# PY32F071Cxx register map
Vendor: Puya; Series: PY32F0; File version: 1.0.0
CPU: CM0+ r0p1, little endian, no MPU, no FPU, 4 interrupt priority bits
Registers are 32-bit, read-write, reset 0x0 unless marked. A register's access mark holds for its fields unless they carry their own. Offsets are from the block's base; [hi:lo] are bit positions; {n}, {i} and the like mark numbered series.

## OPA — des OPA
Base 0x40010300
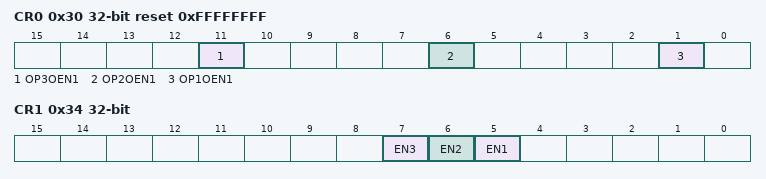
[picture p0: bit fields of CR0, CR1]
0x30 CR0 reset 0xFFFFFFFF
  [11] OP3OEN1, [6] OP2OEN1, [1] OP1OEN1
0x34 CR1
  [7] EN3, [6] EN2, [5] EN1

## PWR — Power control
Base 0x40007000
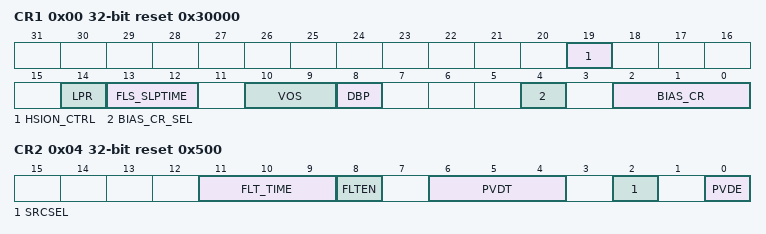
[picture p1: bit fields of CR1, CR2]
0x00 CR1 reset 0x30000 — Power control register 1
  [19] HSION_CTRL — HSI open time control
  [14] LPR — Low-power run
  [13:12] FLS_SLPTIME — Flash wait time after wakeup from the stop mode
  [10:9] VOS — Voltage scaling range selection
  [8] DBP — Disable backup domain write protection
  [4] BIAS_CR_SEL — MR Bias current selection
  [2:0] BIAS_CR — MR Bias current
0x04 CR2 reset 0x500 — Power control register 2
  [11:9] FLT_TIME — Digital filter time configuration
  [8] FLTEN — Digital filter enable
  [6:4] PVDT — Power voltage detector threshold selection
  [2] SRCSEL — Power voltage detector volatage selection
  [0] PVDE — Power voltage detector enable
0x14 SR ro — Power status register
  [11] PVDO — PVD output

## RTC
Base 0x40002800
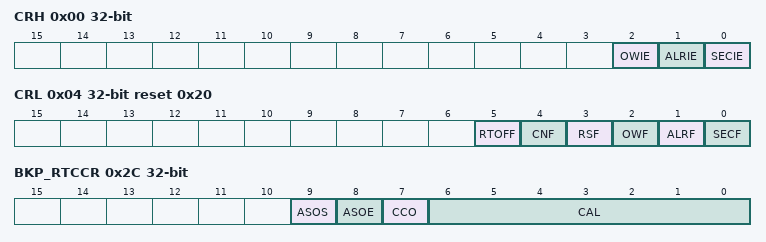
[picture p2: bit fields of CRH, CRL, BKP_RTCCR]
0x00 CRH
  [2] OWIE, [1] ALRIE, [0] SECIE
0x04 CRL reset 0x20
  [5] RTOFF ro, [4] CNF, [3] RSF, [2] OWF, [1] ALRF, [0] SECF
0x08 PRLH wo
  [3:0] PRL
0x0C PRLL wo reset 0x8000
  [15:0] PRL
0x10 DIVH ro
  [3:0] DIV
0x14 DIVL ro reset 0x8000
  [15:0] DIV
0x18 CNTH
  [15:0] RTC_CNT
0x1C CNTL
  [15:0] RTC_CNT
0x20 ALRH reset 0xFFFF
  [15:0] RTC_ALR
0x24 ALRL reset 0xFFFF
  [15:0] RTC_ALR
0x2C BKP_RTCCR
  [9] ASOS, [8] ASOE, [7] CCO, [6:0] CAL

## SPI1 — Serial peripheral interface
Base 0x40013000
Same registers: SPI2 0x40003800
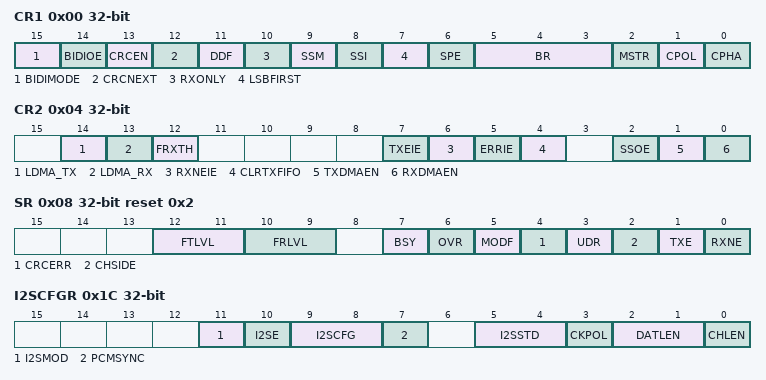
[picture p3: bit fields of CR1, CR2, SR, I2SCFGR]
0x00 CR1
  [15] BIDIMODE, [14] BIDIOE, [13] CRCEN, [12] CRCNEXT, [11] DDF, [10] RXONLY, [9] SSM, [8] SSI, [7] LSBFIRST, [6] SPE, [5:3] BR, [2] MSTR, [1] CPOL, [0] CPHA
0x04 CR2
  [14] LDMA_TX, [13] LDMA_RX, [12] FRXTH, [7] TXEIE, [6] RXNEIE, [5] ERRIE, [4] CLRTXFIFO, [2] SSOE, [1] TXDMAEN, [0] RXDMAEN
0x08 SR reset 0x2
  [12:11] FTLVL ro, [10:9] FRLVL ro, [7] BSY ro, [6] OVR ro, [5] MODF ro, [4] CRCERR, [3] UDR ro, [2] CHSIDE ro, [1] TXE ro, [0] RXNE ro
0x0C DR
  [15:0] DR
0x10 CRCPR reset 0x7
  [15:0] CRCPOLY
0x14 RXCRCR ro
  [15:0] RXCRC
0x18 TXCRCR ro
  [15:0] TXCRC
0x1C I2SCFGR
  [11] I2SMOD, [10] I2SE, [9:8] I2SCFG, [7] PCMSYNC, [5:4] I2SSTD, [3] CKPOL, [2:1] DATLEN, [0] CHLEN
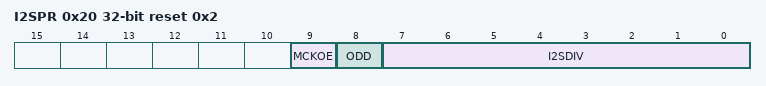
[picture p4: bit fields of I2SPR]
0x20 I2SPR reset 0x2
  [9] MCKOE, [8] ODD, [7:0] I2SDIV

## SYSCFG
Base 0x40010000
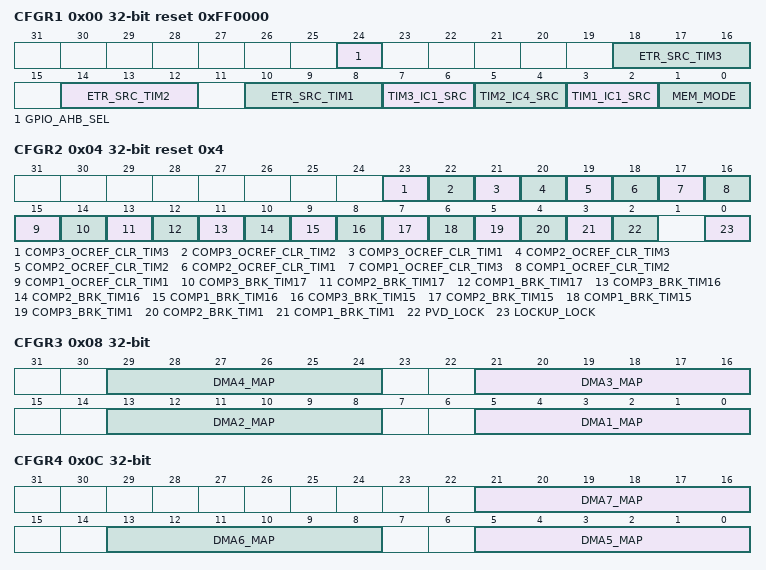
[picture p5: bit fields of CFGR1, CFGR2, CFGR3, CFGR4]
0x00 CFGR1 reset 0xFF0000
  [24] GPIO_AHB_SEL, [18:16] ETR_SRC_TIM3, [14:12] ETR_SRC_TIM2, [10:8] ETR_SRC_TIM1, [7:6] TIM3_IC1_SRC, [5:4] TIM2_IC4_SRC, [3:2] TIM1_IC1_SRC, [1:0] MEM_MODE
0x04 CFGR2 reset 0x4
  [23] COMP3_OCREF_CLR_TIM3, [22] COMP3_OCREF_CLR_TIM2, [21] COMP3_OCREF_CLR_TIM1, [20] COMP2_OCREF_CLR_TIM3, [19] COMP2_OCREF_CLR_TIM2, [18] COMP2_OCREF_CLR_TIM1, [17] COMP1_OCREF_CLR_TIM3, [16] COMP1_OCREF_CLR_TIM2, [15] COMP1_OCREF_CLR_TIM1, [14] COMP3_BRK_TIM17, [13] COMP2_BRK_TIM17, [12] COMP1_BRK_TIM17, [11] COMP3_BRK_TIM16, [10] COMP2_BRK_TIM16, [9] COMP1_BRK_TIM16, [8] COMP3_BRK_TIM15, [7] COMP2_BRK_TIM15, [6] COMP1_BRK_TIM15, [5] COMP3_BRK_TIM1, [4] COMP2_BRK_TIM1, [3] COMP1_BRK_TIM1, [2] PVD_LOCK, [0] LOCKUP_LOCK
0x08 CFGR3
  [8n-3:8n-8] DMA{n}_MAP (n=1..4)
0x0C CFGR4
  [21:16] DMA7_MAP, [13:8] DMA6_MAP, [5:0] DMA5_MAP
0x10 PAENS
  [15:0] PA_ENS
0x14 PBENS
  [15:0] PB_ENS
0x18 PCENS
  [15:0] PC_ENS
0x1C PFENS
  [15:0] PF_ENS

## TIM1 — Advanced timer
Base 0x40012C00
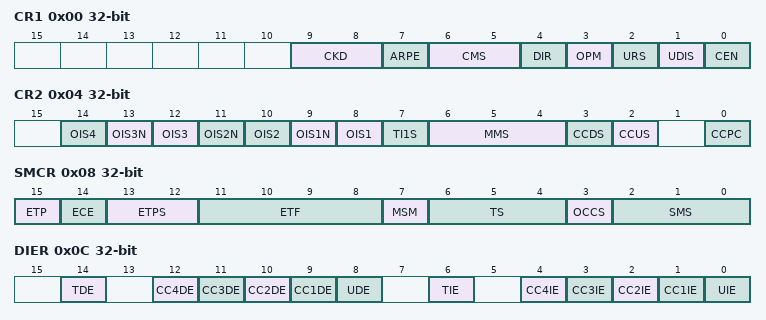
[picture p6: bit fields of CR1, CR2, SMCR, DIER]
0x00 CR1
  [9:8] CKD, [7] ARPE, [6:5] CMS, [4] DIR, [3] OPM, [2] URS, [1] UDIS, [0] CEN
0x04 CR2
  [2n+6] OIS{n} (n=1..4), [13] OIS3N, [11] OIS2N, [9] OIS1N, [7] TI1S, [6:4] MMS, [3] CCDS, [2] CCUS, [0] CCPC
0x08 SMCR (reset mask 0xFFF7)
  [15] ETP, [14] ECE, [13:12] ETPS, [11:8] ETF, [7] MSM, [6:4] TS, [3] OCCS, [2:0] SMS
0x0C DIER
  [14] TDE, [n+8] CC{n}DE (n=1..4), [8] UDE, [6] TIE, [n] CC{n}IE (n=1..4), [0] UIE
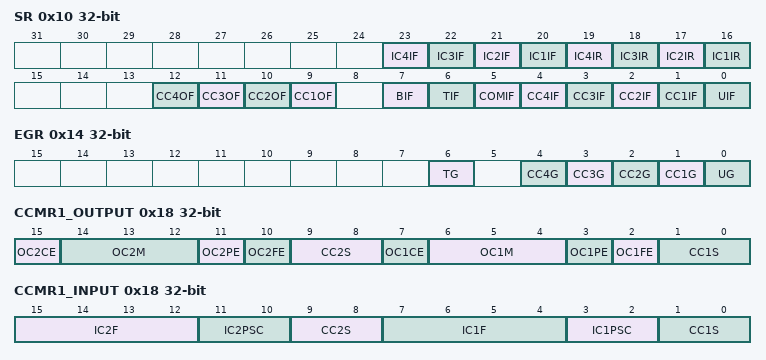
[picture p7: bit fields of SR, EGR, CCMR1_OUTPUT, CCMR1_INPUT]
0x10 SR (reset mask 0x1E5F)
  [23] IC4IF — desc IC3IF
  [22] IC3IF
  [21] IC2IF
  [20] IC1IF
  [19] IC4IR — desc IC3IR
  [18] IC3IR
  [17] IC2IR
  [16] IC1IR
  [n+8] CC{n}OF (n=1..4)
  [7] BIF
  [6] TIF
  [5] COMIF
  [n] CC{n}IF (n=1..4)
  [0] UIF
0x14 EGR wo
  [6] TG
  [4] CC4G
  [3] CC3G
  [2] CC2G
  [1] CC1G — Capture/Compare 1 Generation
  [0] UG
0x18 CCMR1_OUTPUT
  [15] OC2CE, [14:12] OC2M, [11] OC2PE, [10] OC2FE, [9:8] CC2S, [7] OC1CE, [6:4] OC1M, [3] OC1PE, [2] OC1FE, [1:0] CC1S
0x18 CCMR1_INPUT (alternate view of CCMR1_OUTPUT)
  [15:12] IC2F, [11:10] IC2PSC, [9:8] CC2S, [7:4] IC1F, [3:2] IC1PSC, [1:0] CC1S
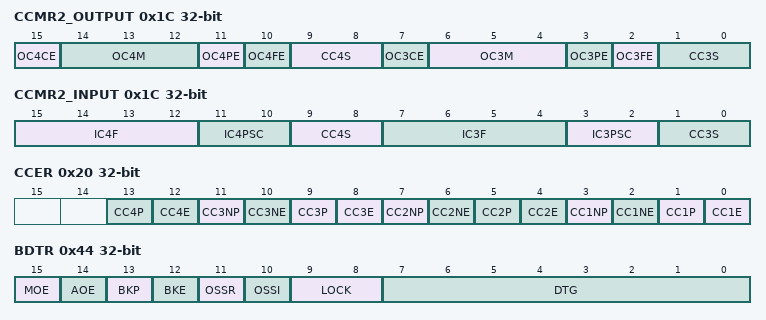
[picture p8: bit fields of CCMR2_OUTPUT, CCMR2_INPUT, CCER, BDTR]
0x1C CCMR2_OUTPUT
  [15] OC4CE, [14:12] OC4M, [11] OC4PE, [10] OC4FE, [9:8] CC4S, [7] OC3CE, [6:4] OC3M, [3] OC3PE, [2] OC3FE, [1:0] CC3S
0x1C CCMR2_INPUT (alternate view of CCMR2_OUTPUT)
  [15:12] IC4F, [11:10] IC4PSC, [9:8] CC4S, [7:4] IC3F, [3:2] IC3PSC, [1:0] CC3S
0x20 CCER (reset mask 0x3333)
  [4n-3] CC{n}P (n=1..4), [4n-4] CC{n}E (n=1..4), [11] CC3NP, [10] CC3NE, [7] CC2NP, [6] CC2NE, [3] CC1NP, [2] CC1NE
0x24 CNT
  [15:0] CNT
0x28 PSC
  [15:0] PSC
0x2C ARR reset 0xFFFF
  [15:0] ARR
0x30 RCR reset 0xFFFF
  [7:0] REP
{0x30+4i} CCR{i} (i=1..4)
  [15:0] CCR{i}
0x44 BDTR
  [15] MOE, [14] AOE, [13] BKP, [12] BKE, [11] OSSR, [10] OSSI, [9:8] LOCK, [7:0] DTG
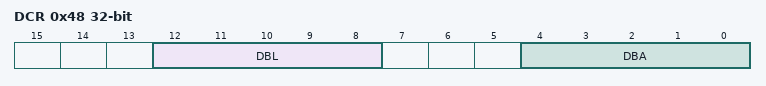
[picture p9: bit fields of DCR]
0x48 DCR
  [12:8] DBL, [4:0] DBA
0x4C DMAR
  [15:0] DMAB

## TIM2 — desc TIM
Base 0x40000000
Same registers: TIM3 0x40000400
Registers as TIM1, without RCR, BDTR; these are added or differ:
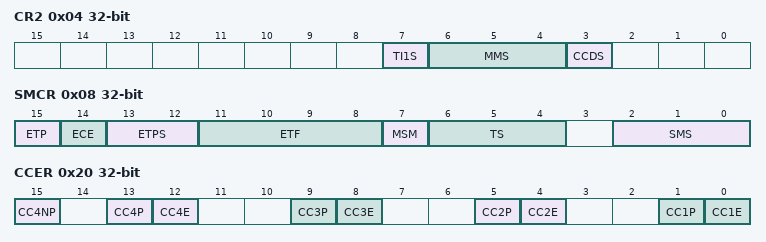
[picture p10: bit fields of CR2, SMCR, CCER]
0x04 CR2
  [7] TI1S, [6:4] MMS, [3] CCDS
0x08 SMCR
  [15] ETP, [14] ECE, [13:12] ETPS, [11:8] ETF, [7] MSM, [6:4] TS, [2:0] SMS
0x20 CCER (reset mask 0x3333)
  [15] CC4NP, [4n-3] CC{n}P (n=1..4), [4n-4] CC{n}E (n=1..4)

## TIM6 — desc TIM
Base 0x40001000
Same registers: TIM7 0x40001400
Registers as TIM2, without SMCR, CCMR1_OUTPUT, CCMR1_INPUT, CCMR2_OUTPUT, CCMR2_INPUT, CCER, CCR{n} (n=1..4), DCR, DMAR.

## TIM14 — General purpose timer
Base 0x40002000
Registers as TIM1, without CR2, SMCR, CCMR2_OUTPUT, CCMR2_INPUT, RCR, CCR{n} (n=2..4), BDTR, DCR, DMAR; these are added or differ:
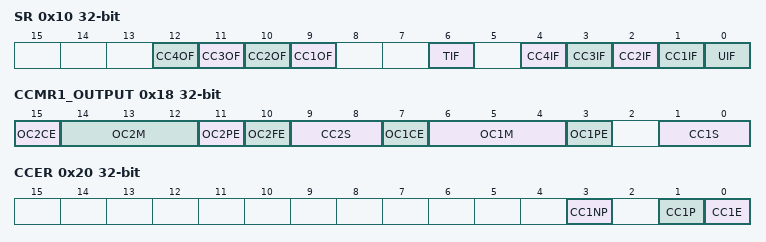
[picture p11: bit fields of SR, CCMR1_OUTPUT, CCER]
0x10 SR
  [n+8] CC{n}OF (n=1..4), [6] TIF, [n] CC{n}IF (n=1..4), [0] UIF
0x18 CCMR1_OUTPUT
  [15] OC2CE, [14:12] OC2M, [11] OC2PE, [10] OC2FE, [9:8] CC2S, [7] OC1CE, [6:4] OC1M, [3] OC1PE, [1:0] CC1S
0x20 CCER (reset mask 0x3333)
  [3] CC1NP, [1] CC1P, [0] CC1E
0x50 OR
  [1:0] TI1_RMP

## TIM15
Base 0x40014000
Registers as TIM1, without CCMR2_OUTPUT, CCMR2_INPUT, CCR3, CCR4; these are added or differ:
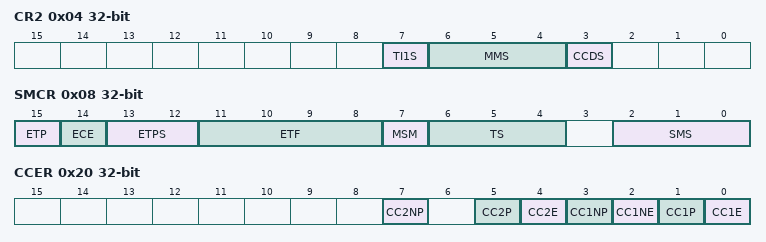
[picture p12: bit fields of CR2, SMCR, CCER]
0x04 CR2
  [7] TI1S, [6:4] MMS, [3] CCDS
0x08 SMCR
  [15] ETP, [14] ECE, [13:12] ETPS, [11:8] ETF, [7] MSM, [6:4] TS, [2:0] SMS
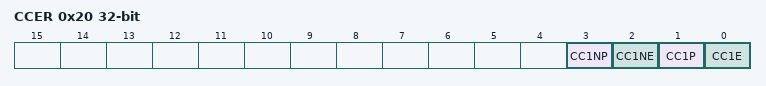
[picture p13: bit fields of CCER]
0x20 CCER (reset mask 0x3333)
  [7] CC2NP, [5] CC2P, [4] CC2E, [3] CC1NP, [2] CC1NE, [1] CC1P, [0] CC1E

## TIM16 — General purpose timer
Base 0x40014400
Same registers: TIM17 0x40014800
Registers as TIM15, without SMCR, CCR2; these are added or differ:
0x20 CCER (reset mask 0x3333)
  [3] CC1NP, [2] CC1NE, [1] CC1P, [0] CC1E

## USART1 — Universal synchronous asynchronous receiver transmitter
Base 0x40013800
Same registers: USART2 0x40004400, USART3 0x40004800, USART4 0x40004C00
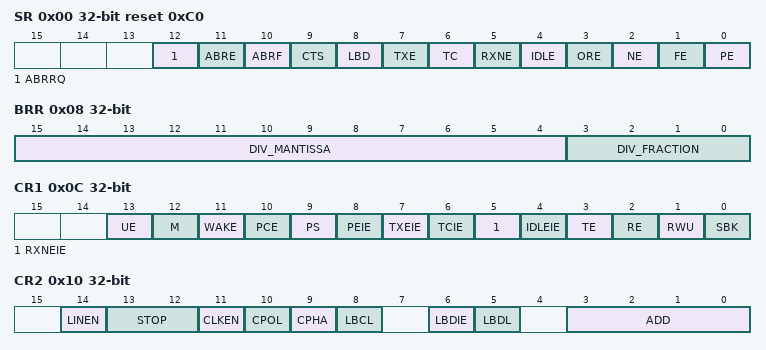
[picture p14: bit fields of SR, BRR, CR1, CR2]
0x00 SR reset 0xC0
  [12] ABRRQ wo, [11] ABRE ro, [10] ABRF ro, [9] CTS, [8] LBD, [7] TXE ro, [6] TC, [5] RXNE, [4] IDLE ro, [3] ORE ro, [2] NE ro, [1] FE ro, [0] PE ro
0x04 DR
  [8:0] DR
0x08 BRR
  [15:4] DIV_MANTISSA, [3:0] DIV_FRACTION
0x0C CR1
  [13] UE, [12] M, [11] WAKE, [10] PCE, [9] PS, [8] PEIE, [7] TXEIE, [6] TCIE, [5] RXNEIE, [4] IDLEIE, [3] TE, [2] RE, [1] RWU, [0] SBK
0x10 CR2
  [14] LINEN, [13:12] STOP, [11] CLKEN, [10] CPOL, [9] CPHA, [8] LBCL, [6] LBDIE, [5] LBDL, [3:0] ADD
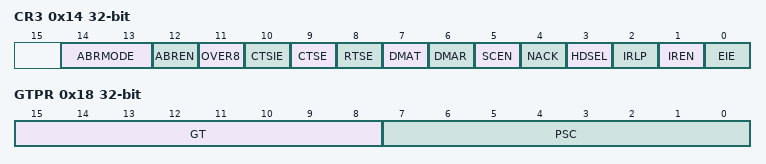
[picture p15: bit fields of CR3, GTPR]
0x14 CR3
  [14:13] ABRMODE, [12] ABREN, [11] OVER8, [10] CTSIE, [9] CTSE, [8] RTSE, [7] DMAT, [6] DMAR, [5] SCEN, [4] NACK, [3] HDSEL, [2] IRLP, [1] IREN, [0] EIE
0x18 GTPR
  [15:8] GT, [7:0] PSC

## USB
Base 0x40005C00
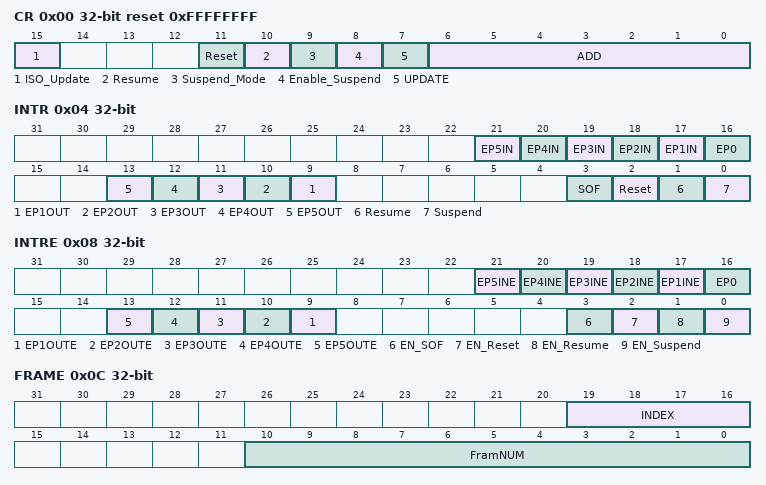
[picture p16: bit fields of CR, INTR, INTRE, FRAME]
0x00 CR reset 0xFFFFFFFF
  [15] ISO_Update, [11] Reset, [10] Resume, [9] Suspend_Mode, [8] Enable_Suspend, [7] UPDATE, [6:0] ADD
0x04 INTR
  [n+16] EP{n}IN (n=1..5), [16] EP0, [n+8] EP{n}OUT (n=1..5), [3] SOF, [2] Reset, [1] Resume, [0] Suspend
0x08 INTRE
  [n+16] EP{n}INE (n=1..5), [16] EP0, [n+8] EP{n}OUTE (n=1..5), [3] EN_SOF, [2] EN_Reset, [1] EN_Resume, [0] EN_Suspend
0x0C FRAME wo
  [19:16] INDEX, [10:0] FramNUM
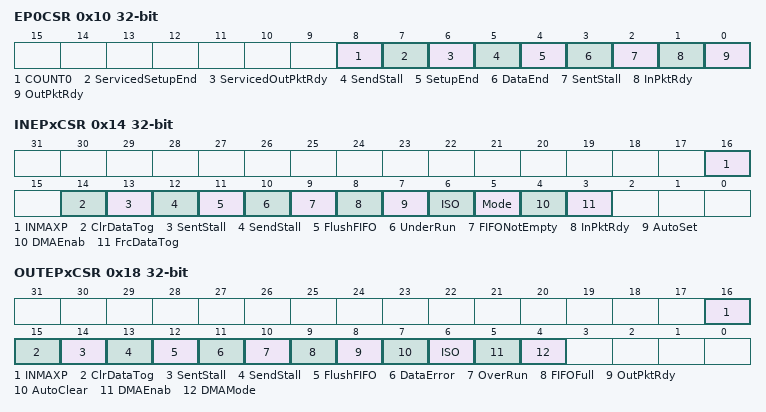
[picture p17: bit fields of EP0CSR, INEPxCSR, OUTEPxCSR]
0x10 EP0CSR wo
  [8] COUNT0
  [7] ServicedSetupEnd
  [6] ServicedOutPktRdy
  [5] SendStall — OutPktRdy
  [4] SetupEnd
  [3] DataEnd
  [2] SentStall
  [1] InPktRdy
  [0] OutPktRdy
0x14 INEPxCSR wo
  [16] INMAXP, [14] ClrDataTog, [13] SentStall, [12] SendStall, [11] FlushFIFO, [10] UnderRun, [9] FIFONotEmpty, [8] InPktRdy, [7] AutoSet, [6] ISO, [5] Mode, [4] DMAEnab, [3] FrcDataTog
0x18 OUTEPxCSR wo
  [16] INMAXP, [15] ClrDataTog, [14] SentStall, [13] SendStall, [12] FlushFIFO, [11] DataError, [10] OverRun, [9] FIFOFull, [8] OutPktRdy, [7] AutoClear, [6] ISO, [5] DMAEnab, [4] DMAMode
0x1C OUTCOUNT wo
  [9:0] OUTCOUNT

## WWDG — Window watchdog
Base 0x40002C00
0x00 CR reset 0x7F — Control register (WWDG_CR)
  [7] WDGA — Activation bit
  [6:0] T — 7-bit counter (MSB to LSB)
0x04 CFR reset 0x7F — Configuration register (WWDG_CFR)
  [9] EWI — Early Wakeup Interrupt
  [8:7] WDGTB — Timer Base
  [6:0] W — 7-bit window value
0x08 SR — Status register (WWDG_SR)
  [0] EWIF — Early Wakeup Interrupt flag
